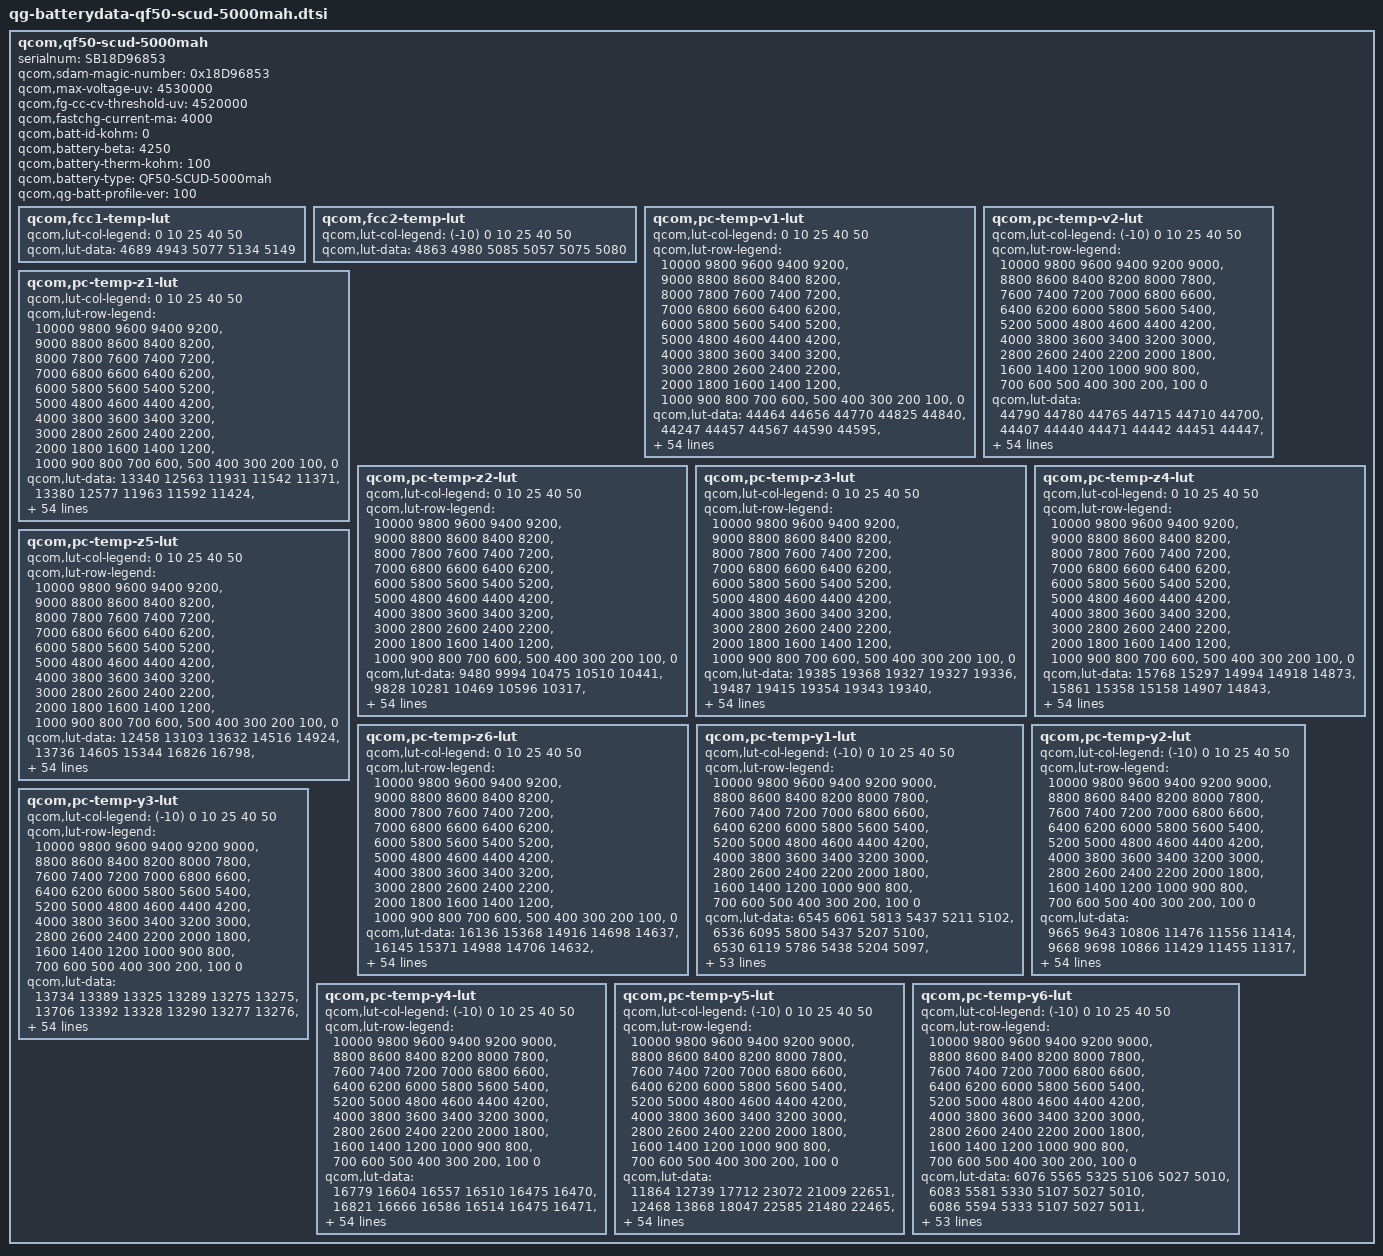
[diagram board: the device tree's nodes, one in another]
/* Copyright (c) 2018, The Linux Foundation. All rights reserved.
 *
 * This program is free software; you can redistribute it and/or modify
 * it under the terms of the GNU General Public License version 2 and
 * only version 2 as published by the Free Software Foundation.
 *
 * This program is distributed in the hope that it will be useful,
 * but WITHOUT ANY WARRANTY; without even the implied warranty of
 * MERCHANTABILITY or FITNESS FOR A PARTICULAR PURPOSE.  See the
 * GNU General Public License for more details.
 */

qcom,qf50-scud-5000mah {
    /* 6691233_Ontim_SQ432_SCUD_5000mAH_PM7250B_averaged_MasterSlave_Sep6th2023 */
    serialnum = "SB18D96853";
    qcom,sdam-magic-number = <0x18D96853>;
    qcom,max-voltage-uv = <4530000>;
    qcom,fg-cc-cv-threshold-uv = <4520000>;
    qcom,fastchg-current-ma = <4000>;
    qcom,batt-id-kohm = <0>;
    qcom,battery-beta = <4250>;
    qcom,battery-therm-kohm = <100>;
    qcom,battery-type = "QF50-SCUD-5000mah";
    qcom,qg-batt-profile-ver = <100>;

	qcom,fcc1-temp-lut {
		qcom,lut-col-legend = <0 10 25 40 50>;
		qcom,lut-data = <4689 4943 5077 5134 5149>;
	};

	qcom,fcc2-temp-lut {
		qcom,lut-col-legend = <(-10) 0 10 25 40 50>;
		qcom,lut-data = <4863 4980 5085 5057 5075 5080>;
	};

	qcom,pc-temp-v1-lut {
		qcom,lut-col-legend = <0 10 25 40 50>;
		qcom,lut-row-legend = <10000 9800 9600 9400 9200>,
			<9000 8800 8600 8400 8200>,
			<8000 7800 7600 7400 7200>,
			<7000 6800 6600 6400 6200>,
			<6000 5800 5600 5400 5200>,
			<5000 4800 4600 4400 4200>,
			<4000 3800 3600 3400 3200>,
			<3000 2800 2600 2400 2200>,
			<2000 1800 1600 1400 1200>,
			<1000 900 800 700 600>,
			<500 400 300 200 100>,
			<0>;
		qcom,lut-data = <44464 44656 44770 44825 44840>,
			<44247 44457 44567 44590 44595>,
			<44029 44254 44372 44395 44395>,
			<43812 44049 44175 44213 44213>,
			<43596 43839 43974 44023 44026>,
			<43373 43621 43767 43820 43827>,
			<43141 43395 43550 43609 43618>,
			<42904 43161 43320 43385 43396>,
			<42664 42915 43080 43150 43161>,
			<42420 42661 42833 42907 42918>,
			<42180 42410 42578 42655 42668>,
			<41944 42162 42325 42401 42414>,
			<41712 41916 42073 42146 42161>,
			<41484 41675 41824 41892 41909>,
			<41262 41440 41580 41644 41661>,
			<41044 41211 41341 41401 41419>,
			<40836 40988 41111 41167 41183>,
			<40633 40773 40889 40943 40953>,
			<40439 40566 40676 40727 40731>,
			<40250 40365 40475 40523 40522>,
			<40067 40167 40278 40331 40332>,
			<39891 39972 40059 40109 40118>,
			<39723 39776 39814 39807 39833>,
			<39560 39568 39574 39519 39548>,
			<39403 39356 39331 39330 39357>,
			<39250 39166 39114 39183 39211>,
			<39109 38994 38979 39052 39072>,
			<38980 38848 38885 38934 38931>,
			<38861 38738 38798 38823 38801>,
			<38754 38647 38707 38710 38689>,
			<38656 38569 38621 38602 38589>,
			<38568 38498 38541 38507 38496>,
			<38497 38434 38466 38423 38411>,
			<38435 38373 38395 38344 38329>,
			<38380 38318 38328 38268 38251>,
			<38330 38265 38263 38195 38175>,
			<38284 38218 38200 38124 38096>,
			<38230 38168 38138 38055 38015>,
			<38169 38099 38061 37973 37923>,
			<38099 38004 37960 37860 37803>,
			<38014 37895 37843 37732 37669>,
			<37909 37762 37712 37608 37538>,
			<37786 37611 37564 37476 37402>,
			<37633 37431 37388 37307 37232>,
			<37455 37276 37232 37157 37089>,
			<37301 37176 37128 37070 37012>,
			<37235 37133 37098 37039 36980>,
			<37180 37103 37070 37019 36958>,
			<37134 37079 37045 36993 36931>,
			<37093 37015 36970 36913 36844>,
			<37038 36773 36688 36617 36532>,
			<36917 36299 36226 36155 36069>,
			<36588 35692 35618 35553 35470>,
			<36036 34841 34782 34727 34646>,
			<35081 33409 33462 33436 33354>,
			<30000 30000 30000 30000 30000>;
	};

	qcom,pc-temp-v2-lut {
		qcom,lut-col-legend = <(-10) 0 10 25 40 50>;
		qcom,lut-row-legend = <10000 9800 9600 9400 9200 9000>,
			<8800 8600 8400 8200 8000 7800>,
			<7600 7400 7200 7000 6800 6600>,
			<6400 6200 6000 5800 5600 5400>,
			<5200 5000 4800 4600 4400 4200>,
			<4000 3800 3600 3400 3200 3000>,
			<2800 2600 2400 2200 2000 1800>,
			<1600 1400 1200 1000 900 800>,
			<700 600 500 400 300 200>,
			<100 0>;
		qcom,lut-data = <44790 44780 44765 44715 44710 44700>,
			<44407 44440 44471 44442 44451 44447>,
			<44068 44142 44206 44190 44210 44211>,
			<43781 43897 43977 43964 43992 43995>,
			<43541 43697 43778 43764 43794 43799>,
			<43314 43500 43576 43559 43591 43597>,
			<43083 43286 43356 43339 43373 43381>,
			<42855 43064 43128 43110 43145 43156>,
			<42621 42834 42890 42873 42909 42921>,
			<42376 42591 42640 42625 42661 42675>,
			<42128 42346 42387 42374 42411 42426>,
			<41884 42103 42134 42123 42159 42175>,
			<41638 41858 41882 41871 41906 41923>,
			<41393 41616 41636 41624 41658 41675>,
			<41151 41379 41395 41380 41414 41429>,
			<40909 41141 41160 41144 41176 41191>,
			<40660 40899 40935 40914 40945 40959>,
			<40404 40655 40708 40693 40722 40735>,
			<40152 40404 40466 40485 40513 40524>,
			<39906 40144 40215 40286 40311 40322>,
			<39665 39890 39959 40064 40094 40108>,
			<39437 39647 39694 39792 39852 39878>,
			<39222 39415 39444 39519 39608 39644>,
			<39018 39201 39226 39292 39369 39402>,
			<38819 39003 39028 39088 39140 39163>,
			<38631 38816 38853 38914 38958 38977>,
			<38481 38631 38698 38767 38815 38832>,
			<38364 38455 38555 38636 38688 38703>,
			<38264 38313 38422 38516 38571 38582>,
			<38176 38195 38297 38407 38463 38470>,
			<38100 38097 38184 38306 38365 38370>,
			<38025 38016 38077 38212 38277 38280>,
			<37949 37947 37984 38124 38191 38194>,
			<37874 37878 37907 38039 38107 38113>,
			<37799 37812 37839 37957 38022 38031>,
			<37724 37744 37776 37872 37926 37929>,
			<37649 37674 37718 37784 37820 37805>,
			<37572 37599 37653 37695 37712 37683>,
			<37494 37518 37580 37609 37609 37573>,
			<37415 37428 37494 37522 37505 37465>,
			<37335 37331 37377 37423 37404 37365>,
			<37254 37228 37224 37313 37301 37264>,
			<37169 37118 37070 37181 37167 37123>,
			<37082 37007 36922 37031 37024 36972>,
			<36997 36889 36802 36902 36916 36869>,
			<36907 36769 36697 36840 36869 36825>,
			<36857 36713 36638 36817 36855 36813>,
			<36807 36661 36571 36786 36837 36793>,
			<36744 36614 36484 36740 36801 36754>,
			<36672 36549 36355 36628 36689 36626>,
			<36596 36448 36094 36307 36349 36261>,
			<36527 36285 35537 35777 35830 35733>,
			<36382 35715 34709 35082 35149 35042>,
			<36077 35032 33716 34072 34187 34063>,
			<35938 34389 32344 32561 32755 32608>,
			<35804 33409 28433 28113 28178 28204>;
	};

	qcom,pc-temp-z1-lut {
		qcom,lut-col-legend = <0 10 25 40 50>;
		qcom,lut-row-legend = <10000 9800 9600 9400 9200>,
			<9000 8800 8600 8400 8200>,
			<8000 7800 7600 7400 7200>,
			<7000 6800 6600 6400 6200>,
			<6000 5800 5600 5400 5200>,
			<5000 4800 4600 4400 4200>,
			<4000 3800 3600 3400 3200>,
			<3000 2800 2600 2400 2200>,
			<2000 1800 1600 1400 1200>,
			<1000 900 800 700 600>,
			<500 400 300 200 100>,
			<0>;
		qcom,lut-data = <13340 12563 11931 11542 11371>,
			<13380 12577 11963 11592 11424>,
			<13400 12588 11990 11592 11417>,
			<13395 12590 12010 11583 11410>,
			<13373 12586 12004 11574 11403>,
			<13358 12576 11983 11567 11395>,
			<13323 12550 11968 11559 11387>,
			<13284 12520 11958 11552 11381>,
			<13258 12499 11950 11544 11375>,
			<13207 12481 11943 11535 11370>,
			<13163 12464 11937 11525 11366>,
			<13149 12444 11929 11516 11363>,
			<13140 12426 11915 11512 11360>,
			<13121 12410 11906 11510 11358>,
			<13058 12395 11908 11508 11356>,
			<12993 12391 11912 11506 11354>,
			<12975 12392 11914 11504 11354>,
			<12966 12392 11914 11502 11354>,
			<12962 12389 11913 11500 11354>,
			<12945 12386 11914 11501 11354>,
			<12920 12388 11915 11503 11353>,
			<12915 12393 11918 11505 11353>,
			<12919 12398 11925 11505 11352>,
			<12925 12403 11930 11505 11352>,
			<12931 12409 11931 11506 11352>,
			<12939 12412 11931 11508 11354>,
			<12946 12416 11933 11511 11356>,
			<12952 12419 11936 11514 11358>,
			<12959 12423 11940 11519 11361>,
			<12968 12432 11949 11522 11364>,
			<12982 12435 11957 11526 11368>,
			<12993 12440 11961 11530 11371>,
			<12991 12447 11966 11536 11375>,
			<12984 12447 11969 11542 11379>,
			<12981 12448 11969 11547 11384>,
			<12996 12451 11971 11551 11390>,
			<13018 12469 11976 11557 11395>,
			<13026 12492 11985 11565 11400>,
			<13027 12500 11995 11572 11405>,
			<13028 12504 12006 11579 11412>,
			<13028 12509 12017 11587 11419>,
			<13028 12521 12027 11595 11424>,
			<13044 12538 12035 11603 11428>,
			<13089 12572 12039 11608 11432>,
			<13180 12580 12046 11614 11437>,
			<13120 12581 12068 11619 11441>,
			<13122 12581 12047 11619 11440>,
			<13120 12586 12056 11623 11442>,
			<13110 12601 12062 11626 11447>,
			<13108 12580 12067 11636 11452>,
			<13120 12619 12081 11637 11458>,
			<13115 12634 12084 11649 11468>,
			<13182 12797 12113 11659 11476>,
			<13134 12675 12129 11677 11492>,
			<13134 12675 12129 11677 11492>,
			<13134 12675 12129 11677 11492>;
	};

	qcom,pc-temp-z2-lut {
		qcom,lut-col-legend = <0 10 25 40 50>;
		qcom,lut-row-legend = <10000 9800 9600 9400 9200>,
			<9000 8800 8600 8400 8200>,
			<8000 7800 7600 7400 7200>,
			<7000 6800 6600 6400 6200>,
			<6000 5800 5600 5400 5200>,
			<5000 4800 4600 4400 4200>,
			<4000 3800 3600 3400 3200>,
			<3000 2800 2600 2400 2200>,
			<2000 1800 1600 1400 1200>,
			<1000 900 800 700 600>,
			<500 400 300 200 100>,
			<0>;
		qcom,lut-data = <9480 9994 10475 10510 10441>,
			<9828 10281 10469 10596 10317>,
			<10056 10456 10660 10724 10497>,
			<10199 10531 10854 10711 10605>,
			<10347 10574 10855 10690 10642>,
			<10383 10572 10803 10673 10613>,
			<10378 10537 10755 10652 10563>,
			<10371 10508 10704 10610 10517>,
			<10363 10496 10649 10544 10466>,
			<10352 10487 10589 10485 10420>,
			<10342 10472 10529 10426 10377>,
			<10328 10435 10512 10391 10340>,
			<10310 10409 10511 10389 10312>,
			<10295 10402 10509 10393 10290>,
			<10281 10397 10507 10398 10272>,
			<10268 10397 10504 10410 10252>,
			<10256 10399 10505 10414 10240>,
			<10245 10402 10519 10363 10248>,
			<10240 10409 10533 10299 10264>,
			<10242 10422 10537 10294 10271>,
			<10247 10434 10541 10309 10275>,
			<10250 10447 10576 10340 10279>,
			<10255 10463 10713 10506 10319>,
			<10262 10493 10794 10667 10372>,
			<10273 10532 10745 10590 10374>,
			<10294 10552 10661 10372 10350>,
			<10310 10561 10605 10302 10374>,
			<10319 10566 10557 10327 10814>,
			<10326 10561 10539 10371 11219>,
			<10334 10547 10558 10514 11096>,
			<10346 10539 10587 10722 10759>,
			<10357 10534 10605 10754 10533>,
			<10360 10530 10620 10659 10369>,
			<10361 10532 10630 10552 10276>,
			<10361 10540 10637 10457 10247>,
			<10357 10544 10643 10382 10232>,
			<10351 10542 10646 10380 10246>,
			<10350 10540 10647 10417 10304>,
			<10352 10543 10651 10461 10362>,
			<10354 10553 10670 10525 10415>,
			<10286 10558 10685 10577 10456>,
			<10064 10547 10680 10572 10467>,
			<9927 10530 10668 10549 10468>,
			<9716 10510 10650 10550 10462>,
			<9960 10529 10631 10552 10463>,
			<9951 10532 10621 10558 10451>,
			<9949 10508 10591 10532 10431>,
			<9987 10443 10543 10546 10442>,
			<9968 10501 10536 10567 10495>,
			<9871 10655 10582 10646 10543>,
			<9864 13526 10583 10573 10446>,
			<9770 10302 10560 10396 10264>,
			<9680 10092 10498 10350 10175>,
			<9490 9962 10407 10281 10113>,
			<9490 9962 10407 10281 10113>,
			<9490 9962 10407 10281 10113>;
	};

	qcom,pc-temp-z3-lut {
		qcom,lut-col-legend = <0 10 25 40 50>;
		qcom,lut-row-legend = <10000 9800 9600 9400 9200>,
			<9000 8800 8600 8400 8200>,
			<8000 7800 7600 7400 7200>,
			<7000 6800 6600 6400 6200>,
			<6000 5800 5600 5400 5200>,
			<5000 4800 4600 4400 4200>,
			<4000 3800 3600 3400 3200>,
			<3000 2800 2600 2400 2200>,
			<2000 1800 1600 1400 1200>,
			<1000 900 800 700 600>,
			<500 400 300 200 100>,
			<0>;
		qcom,lut-data = <19385 19368 19327 19327 19336>,
			<19487 19415 19354 19343 19340>,
			<19553 19449 19381 19360 19364>,
			<19579 19474 19403 19366 19369>,
			<19597 19491 19413 19372 19374>,
			<19601 19496 19419 19382 19381>,
			<19598 19498 19423 19391 19387>,
			<19595 19499 19426 19395 19392>,
			<19593 19501 19429 19398 19397>,
			<19591 19502 19429 19399 19398>,
			<19590 19501 19428 19397 19396>,
			<19588 19498 19427 19395 19393>,
			<19585 19493 19422 19392 19389>,
			<19583 19487 19415 19389 19385>,
			<19582 19482 19411 19386 19381>,
			<19581 19478 19408 19383 19376>,
			<19578 19475 19405 19379 19373>,
			<19572 19472 19402 19374 19369>,
			<19567 19469 19399 19368 19366>,
			<19563 19465 19395 19363 19362>,
			<19560 19464 19392 19359 19357>,
			<19558 19464 19394 19358 19355>,
			<19558 19464 19404 19364 19355>,
			<19559 19468 19411 19371 19357>,
			<19561 19476 19408 19364 19352>,
			<19566 19479 19402 19346 19337>,
			<19569 19480 19397 19340 19334>,
			<19569 19479 19391 19341 19373>,
			<19569 19478 19389 19343 19410>,
			<19568 19475 19389 19356 19408>,
			<19568 19471 19390 19378 19401>,
			<19566 19468 19391 19382 19393>,
			<19564 19465 19393 19380 19385>,
			<19560 19464 19395 19377 19376>,
			<19556 19463 19396 19372 19366>,
			<19553 19463 19397 19365 19356>,
			<19550 19461 19396 19359 19349>,
			<19546 19458 19392 19351 19343>,
			<19540 19455 19389 19348 19339>,
			<19533 19451 19386 19348 19337>,
			<19500 19447 19383 19348 19336>,
			<19414 19443 19380 19347 19338>,
			<19359 19439 19377 19344 19341>,
			<19269 19437 19375 19346 19345>,
			<19263 19427 19369 19346 19345>,
			<19263 19405 19363 19335 19334>,
			<19263 19405 19358 19333 19330>,
			<19263 19378 19357 19327 19323>,
			<19263 19267 19351 19324 19316>,
			<19264 19265 19344 19322 19317>,
			<19264 19264 19350 19337 19334>,
			<19265 19364 19355 19349 19344>,
			<19266 19322 19354 19350 19343>,
			<19281 19341 19355 19352 19342>,
			<19281 19341 19355 19352 19342>,
			<19281 19341 19355 19352 19342>;
	};

	qcom,pc-temp-z4-lut {
		qcom,lut-col-legend = <0 10 25 40 50>;
		qcom,lut-row-legend = <10000 9800 9600 9400 9200>,
			<9000 8800 8600 8400 8200>,
			<8000 7800 7600 7400 7200>,
			<7000 6800 6600 6400 6200>,
			<6000 5800 5600 5400 5200>,
			<5000 4800 4600 4400 4200>,
			<4000 3800 3600 3400 3200>,
			<3000 2800 2600 2400 2200>,
			<2000 1800 1600 1400 1200>,
			<1000 900 800 700 600>,
			<500 400 300 200 100>,
			<0>;
		qcom,lut-data = <15768 15297 14994 14918 14873>,
			<15861 15358 15158 14907 14843>,
			<15882 15372 15125 14949 14898>,
			<15803 15312 15071 14910 14868>,
			<15624 15194 15018 14872 14837>,
			<15473 15102 14958 14841 14813>,
			<15355 15026 14908 14813 14792>,
			<15252 14962 14866 14788 14773>,
			<15169 14910 14831 14767 14756>,
			<15097 14866 14801 14748 14741>,
			<15037 14831 14776 14730 14729>,
			<14985 14801 14755 14718 14720>,
			<14941 14776 14737 14711 14716>,
			<14904 14755 14724 14706 14714>,
			<14873 14737 14716 14701 14711>,
			<14846 14728 14711 14697 14707>,
			<14825 14722 14706 14693 14704>,
			<14808 14718 14702 14690 14701>,
			<14795 14715 14698 14687 14698>,
			<14785 14712 14694 14682 14693>,
			<14778 14712 14692 14676 14686>,
			<14773 14713 14695 14676 14684>,
			<14770 14714 14716 14729 14733>,
			<14768 14722 14745 14792 14796>,
			<14768 14742 14792 14812 14810>,
			<14769 14759 14836 14823 14816>,
			<14770 14775 14839 14825 14814>,
			<14773 14785 14823 14811 14763>,
			<14777 14783 14807 14790 14711>,
			<14780 14776 14792 14763 14702>,
			<14783 14769 14778 14731 14699>,
			<14784 14761 14764 14714 14694>,
			<14784 14753 14751 14703 14690>,
			<14781 14747 14740 14696 14685>,
			<14777 14742 14730 14692 14681>,
			<14772 14737 14722 14688 14678>,
			<14765 14730 14718 14685 14675>,
			<14756 14724 14715 14682 14673>,
			<14743 14718 14714 14681 14673>,
			<14730 14713 14714 14690 14686>,
			<14746 14706 14714 14701 14701>,
			<14816 14697 14708 14697 14698>,
			<14861 14688 14697 14688 14689>,
			<14939 14679 14691 14688 14692>,
			<14890 14659 14674 14681 14688>,
			<14890 14651 14650 14656 14658>,
			<14890 14646 14642 14650 14652>,
			<14889 14669 14633 14638 14641>,
			<14889 14788 14626 14620 14622>,
			<14886 14784 14627 14618 14616>,
			<14884 14785 14642 14641 14653>,
			<14882 14694 14647 14647 14663>,
			<14894 14754 14652 14651 14672>,
			<14916 14759 14658 14656 14679>,
			<14916 14759 14658 14656 14679>,
			<14916 14759 14658 14656 14679>;
	};

	qcom,pc-temp-z5-lut {
		qcom,lut-col-legend = <0 10 25 40 50>;
		qcom,lut-row-legend = <10000 9800 9600 9400 9200>,
			<9000 8800 8600 8400 8200>,
			<8000 7800 7600 7400 7200>,
			<7000 6800 6600 6400 6200>,
			<6000 5800 5600 5400 5200>,
			<5000 4800 4600 4400 4200>,
			<4000 3800 3600 3400 3200>,
			<3000 2800 2600 2400 2200>,
			<2000 1800 1600 1400 1200>,
			<1000 900 800 700 600>,
			<500 400 300 200 100>,
			<0>;
		qcom,lut-data = <12458 13103 13632 14516 14924>,
			<13736 14605 15344 16826 16798>,
			<14841 15819 16835 17866 19005>,
			<15762 16748 18120 18425 20004>,
			<16568 17504 18829 19058 20829>,
			<17239 18144 19319 19978 21728>,
			<17786 18683 19863 21001 22729>,
			<18308 19312 20571 21890 24044>,
			<18910 20275 21392 22743 25688>,
			<19572 21420 22297 23710 27142>,
			<20272 22413 23284 24857 28490>,
			<20994 23257 24237 25935 29436>,
			<21765 24194 25170 26810 29725>,
			<22651 25511 26098 27661 29807>,
			<23777 27043 27003 28741 30024>,
			<24905 28295 27906 30195 30701>,
			<25753 29316 28894 30940 31499>,
			<26447 30265 30034 30762 32836>,
			<27114 31110 31112 30505 34793>,
			<27791 31919 31836 30749 36151>,
			<28456 33054 32586 31622 37436>,
			<29177 34747 35850 32986 37931>,
			<30097 37147 46617 36766 36584>,
			<31336 42352 52815 40112 33818>,
			<33335 49909 48871 35942 28910>,
			<36538 52409 41886 24638 20907>,
			<38981 51917 36791 19924 18533>,
			<40067 51001 32122 18910 27056>,
			<40849 48997 30057 18490 35165>,
			<41422 45332 29688 20775 35458>,
			<42113 42776 29508 25766 35222>,
			<42620 41128 29855 28597 35191>,
			<42417 40127 31369 30368 35222>,
			<41445 40338 33346 31806 34957>,
			<40694 41418 36757 33272 33721>,
			<40485 42427 40019 34394 32246>,
			<40309 43175 41468 34432 32051>,
			<40184 43884 42506 34029 32188>,
			<39996 44644 42728 33848 32244>,
			<39657 45495 42181 34785 31412>,
			<36543 45839 41327 35838 30295>,
			<27594 44517 39640 33957 29862>,
			<21738 43463 37606 29882 29624>,
			<11614 45740 37549 31882 32016>,
			<11503 45268 39072 33655 33964>,
			<11439 31446 40440 29490 28539>,
			<11420 31543 36532 28679 25972>,
			<11392 20941 38420 28277 24753>,
			<11319 11519 33805 34532 29248>,
			<11260 11492 29542 33302 36836>,
			<11234 11682 29224 32033 29811>,
			<11216 17161 26795 30104 25131>,
			<11209 13906 23469 26485 20830>,
			<12090 15413 21805 23002 17424>,
			<12090 15413 21805 23002 17424>,
			<12090 15413 21805 23002 17424>;
	};

	qcom,pc-temp-z6-lut {
		qcom,lut-col-legend = <0 10 25 40 50>;
		qcom,lut-row-legend = <10000 9800 9600 9400 9200>,
			<9000 8800 8600 8400 8200>,
			<8000 7800 7600 7400 7200>,
			<7000 6800 6600 6400 6200>,
			<6000 5800 5600 5400 5200>,
			<5000 4800 4600 4400 4200>,
			<4000 3800 3600 3400 3200>,
			<3000 2800 2600 2400 2200>,
			<2000 1800 1600 1400 1200>,
			<1000 900 800 700 600>,
			<500 400 300 200 100>,
			<0>;
		qcom,lut-data = <16136 15368 14916 14698 14637>,
			<16145 15371 14988 14706 14632>,
			<16131 15366 14973 14728 14666>,
			<16069 15326 14947 14711 14655>,
			<15947 15254 14920 14695 14644>,
			<15836 15195 14886 14684 14637>,
			<15743 15141 14857 14674 14630>,
			<15658 15094 14832 14664 14624>,
			<15586 15054 14809 14654 14618>,
			<15522 15020 14789 14644 14612>,
			<15467 14989 14770 14634 14605>,
			<15417 14961 14754 14625 14598>,
			<15373 14938 14740 14619 14594>,
			<15334 14917 14730 14615 14590>,
			<15300 14900 14723 14610 14586>,
			<15270 14891 14718 14606 14582>,
			<15242 14886 14713 14602 14577>,
			<15216 14883 14709 14597 14574>,
			<15197 14880 14706 14592 14571>,
			<15185 14878 14703 14587 14566>,
			<15177 14877 14701 14583 14560>,
			<15175 14879 14703 14582 14558>,
			<15176 14882 14718 14611 14580>,
			<15178 14889 14735 14640 14608>,
			<15182 14902 14755 14641 14609>,
			<15187 14913 14772 14640 14606>,
			<15193 14923 14772 14637 14604>,
			<15198 14928 14764 14632 14603>,
			<15202 14928 14756 14626 14601>,
			<15206 14925 14752 14623 14598>,
			<15209 14922 14748 14621 14593>,
			<15211 14919 14744 14618 14587>,
			<15212 14916 14741 14613 14582>,
			<15213 14916 14740 14609 14576>,
			<15214 14917 14739 14605 14569>,
			<15215 14918 14738 14601 14563>,
			<15217 14918 14738 14598 14559>,
			<15218 14919 14739 14594 14555>,
			<15221 14920 14740 14592 14554>,
			<15224 14923 14743 14598 14559>,
			<15227 14926 14746 14604 14565>,
			<15231 14928 14745 14603 14566>,
			<15237 14931 14744 14600 14565>,
			<15249 14937 14746 14602 14568>,
			<15258 14937 14743 14600 14567>,
			<15264 14931 14735 14585 14549>,
			<15266 14931 14730 14581 14545>,
			<15267 14927 14727 14574 14537>,
			<15268 14927 14723 14566 14525>,
			<15270 14932 14726 14566 14525>,
			<15276 14943 14740 14585 14550>,
			<15290 14962 14751 14596 14562>,
			<15308 14976 14760 14602 14569>,
			<15338 15004 14773 14610 14575>,
			<15338 15004 14773 14610 14575>,
			<15338 15004 14773 14610 14575>;
	};

	qcom,pc-temp-y1-lut {
		qcom,lut-col-legend = <(-10) 0 10 25 40 50>;
		qcom,lut-row-legend = <10000 9800 9600 9400 9200 9000>,
			<8800 8600 8400 8200 8000 7800>,
			<7600 7400 7200 7000 6800 6600>,
			<6400 6200 6000 5800 5600 5400>,
			<5200 5000 4800 4600 4400 4200>,
			<4000 3800 3600 3400 3200 3000>,
			<2800 2600 2400 2200 2000 1800>,
			<1600 1400 1200 1000 900 800>,
			<700 600 500 400 300 200>,
			<100 0>;
		qcom,lut-data = <6545 6061 5813 5437 5211 5102>,
			<6536 6095 5800 5437 5207 5100>,
			<6530 6119 5786 5438 5204 5097>,
			<6526 6135 5774 5439 5200 5094>,
			<6525 6144 5766 5439 5196 5091>,
			<6524 6147 5763 5440 5193 5088>,
			<6536 6138 5765 5440 5188 5084>,
			<6562 6124 5768 5440 5184 5080>,
			<6570 6123 5771 5439 5182 5078>,
			<6556 6128 5774 5435 5180 5076>,
			<6539 6131 5775 5431 5178 5073>,
			<6534 6138 5768 5428 5174 5070>,
			<6534 6151 5760 5425 5170 5068>,
			<6535 6154 5760 5423 5167 5065>,
			<6538 6154 5763 5419 5163 5063>,
			<6543 6154 5764 5418 5160 5063>,
			<6543 6154 5765 5420 5158 5063>,
			<6542 6153 5766 5423 5157 5062>,
			<6540 6154 5769 5422 5157 5062>,
			<6537 6157 5775 5420 5157 5061>,
			<6532 6159 5777 5420 5158 5060>,
			<6534 6157 5771 5422 5158 5060>,
			<6555 6152 5767 5426 5158 5060>,
			<6572 6152 5768 5429 5160 5061>,
			<6573 6165 5772 5432 5162 5062>,
			<6572 6175 5776 5435 5164 5064>,
			<6571 6168 5783 5437 5165 5065>,
			<6557 6154 5787 5440 5166 5066>,
			<6543 6149 5787 5443 5168 5067>,
			<6543 6153 5785 5448 5170 5068>,
			<6548 6156 5785 5450 5173 5070>,
			<6550 6150 5787 5451 5176 5073>,
			<6540 6139 5789 5451 5179 5075>,
			<6527 6135 5785 5452 5182 5078>,
			<6525 6142 5780 5454 5185 5080>,
			<6524 6147 5780 5456 5188 5082>,
			<6523 6143 5788 5458 5190 5084>,
			<6533 6133 5793 5460 5192 5086>,
			<6551 6131 5795 5463 5193 5087>,
			<6553 6139 5796 5465 5195 5088>,
			<6532 6146 5792 5466 5196 5090>,
			<6515 6144 5780 5463 5198 5093>,
			<6518 6141 5776 5463 5199 5095>,
			<6524 6134 5778 5469 5203 5097>,
			<6527 6133 5783 5484 5209 5101>,
			<6542 6156 5970 5475 5211 5103>,
			<6575 6149 5817 5488 5213 5104>,
			<6587 6139 5794 5485 5212 5104>,
			<6664 6164 5777 5480 5214 5106>,
			<6772 6174 5779 5478 5215 5105>,
			<6796 6255 5822 5482 5217 5109>,
			<6867 6342 5884 5490 5223 5114>,
			<6956 6678 6057 5506 5229 5119>,
			<7317 6768 6471 5526 5240 5131>,
			<7317 6768 6471 5526 5240 5131>,
			<7317 6768 6471 5526 5240 5131>;
	};

	qcom,pc-temp-y2-lut {
		qcom,lut-col-legend = <(-10) 0 10 25 40 50>;
		qcom,lut-row-legend = <10000 9800 9600 9400 9200 9000>,
			<8800 8600 8400 8200 8000 7800>,
			<7600 7400 7200 7000 6800 6600>,
			<6400 6200 6000 5800 5600 5400>,
			<5200 5000 4800 4600 4400 4200>,
			<4000 3800 3600 3400 3200 3000>,
			<2800 2600 2400 2200 2000 1800>,
			<1600 1400 1200 1000 900 800>,
			<700 600 500 400 300 200>,
			<100 0>;
		qcom,lut-data = <9665 9643 10806 11476 11556 11414>,
			<9668 9698 10866 11429 11455 11317>,
			<9671 10016 10954 11382 11344 11211>,
			<9674 10361 11046 11337 11235 11108>,
			<9677 10650 11116 11298 11140 11023>,
			<9681 10801 11142 11269 11072 10969>,
			<9685 10842 11133 11249 11020 10942>,
			<9688 10868 11121 11231 10979 10921>,
			<9691 10887 11117 11203 10960 10891>,
			<9692 10903 11122 11165 10945 10853>,
			<9693 10916 11125 11148 10934 10836>,
			<9694 10928 11129 11158 10929 10834>,
			<9696 10940 11138 11178 10928 10832>,
			<9696 10963 11154 11201 10927 10826>,
			<9693 11015 11189 11233 10930 10815>,
			<9689 11057 11230 11269 10942 10807>,
			<9688 11075 11287 11315 10966 10803>,
			<9687 11087 11333 11365 11003 10801>,
			<9687 11088 11344 11419 11092 10829>,
			<9684 11078 11342 11479 11247 10916>,
			<9681 11061 11327 11497 11334 11024>,
			<9678 11037 11271 11444 11337 11202>,
			<9677 11002 11226 11377 11316 11323>,
			<9676 10968 11220 11349 11283 11267>,
			<9675 10936 11218 11330 11232 11150>,
			<9674 10883 11215 11322 11228 11122>,
			<9673 10556 11210 11356 11243 11145>,
			<9672 10008 11203 11394 11264 11166>,
			<9671 9808 11179 11411 11324 11183>,
			<9670 9757 11144 11440 11408 11203>,
			<9668 9730 11136 11463 11428 11221>,
			<9667 9718 11149 11491 11429 11304>,
			<9667 9711 11156 11507 11429 11367>,
			<9666 9703 11137 11482 11435 11387>,
			<9666 9696 11099 11424 11449 11404>,
			<9665 9689 11048 11386 11451 11398>,
			<9664 9683 10969 11355 11427 11372>,
			<9664 9678 10870 11342 11404 11347>,
			<9664 9674 10760 11364 11382 11303>,
			<9663 9671 10611 11398 11355 11253>,
			<9663 9668 10289 11399 11356 11235>,
			<9662 9666 9826 11364 11382 11227>,
			<9661 9664 9719 11264 11347 11190>,
			<9660 9662 9689 11042 11248 11114>,
			<9659 9661 9679 10878 11204 11052>,
			<9657 9659 9671 10980 11104 10941>,
			<9655 9658 9666 10986 11162 10922>,
			<9653 9656 9661 10985 11237 10965>,
			<9651 9653 9658 11055 11251 10963>,
			<9650 9651 9655 11104 11228 10928>,
			<9649 9649 9652 10908 11072 10844>,
			<9648 9648 9650 10589 11002 10785>,
			<9648 9648 9649 10463 10917 10692>,
			<9648 9649 9648 10017 10750 10519>,
			<9648 9649 9648 10017 10750 10519>,
			<9648 9649 9648 10017 10750 10519>;
	};

	qcom,pc-temp-y3-lut {
		qcom,lut-col-legend = <(-10) 0 10 25 40 50>;
		qcom,lut-row-legend = <10000 9800 9600 9400 9200 9000>,
			<8800 8600 8400 8200 8000 7800>,
			<7600 7400 7200 7000 6800 6600>,
			<6400 6200 6000 5800 5600 5400>,
			<5200 5000 4800 4600 4400 4200>,
			<4000 3800 3600 3400 3200 3000>,
			<2800 2600 2400 2200 2000 1800>,
			<1600 1400 1200 1000 900 800>,
			<700 600 500 400 300 200>,
			<100 0>;
		qcom,lut-data = <13734 13389 13325 13289 13275 13275>,
			<13706 13392 13328 13290 13277 13276>,
			<13679 13395 13331 13291 13278 13277>,
			<13653 13398 13335 13292 13280 13278>,
			<13630 13400 13337 13293 13281 13279>,
			<13613 13401 13339 13295 13282 13280>,
			<13601 13400 13340 13296 13283 13281>,
			<13592 13400 13340 13297 13284 13282>,
			<13582 13399 13340 13298 13285 13283>,
			<13571 13397 13340 13299 13285 13284>,
			<13561 13394 13340 13300 13286 13285>,
			<13551 13392 13339 13300 13287 13286>,
			<13542 13389 13337 13301 13288 13287>,
			<13535 13387 13336 13301 13288 13287>,
			<13531 13384 13334 13300 13289 13287>,
			<13528 13381 13333 13300 13289 13287>,
			<13523 13377 13332 13298 13290 13288>,
			<13517 13373 13331 13297 13291 13289>,
			<13512 13368 13329 13297 13291 13290>,
			<13508 13362 13326 13297 13292 13292>,
			<13505 13356 13322 13297 13292 13292>,
			<13504 13351 13318 13295 13289 13290>,
			<13502 13347 13314 13292 13285 13286>,
			<13501 13343 13311 13290 13282 13282>,
			<13499 13339 13309 13288 13279 13278>,
			<13495 13336 13308 13287 13278 13277>,
			<13495 13333 13306 13287 13278 13278>,
			<13505 13331 13305 13286 13278 13278>,
			<13523 13330 13304 13287 13278 13277>,
			<13544 13330 13303 13287 13278 13275>,
			<13572 13331 13303 13287 13278 13275>,
			<13602 13334 13303 13287 13278 13275>,
			<13632 13342 13303 13286 13278 13275>,
			<13665 13351 13303 13286 13278 13277>,
			<13705 13363 13303 13285 13278 13278>,
			<13754 13378 13305 13285 13278 13278>,
			<13807 13399 13307 13285 13278 13277>,
			<13863 13426 13310 13285 13277 13277>,
			<13924 13461 13314 13285 13277 13277>,
			<13991 13507 13319 13285 13278 13277>,
			<14066 13565 13329 13286 13278 13278>,
			<14147 13635 13344 13286 13278 13279>,
			<14232 13723 13359 13287 13277 13278>,
			<14333 13837 13382 13287 13276 13276>,
			<14471 13984 13425 13288 13277 13276>,
			<14729 14175 13508 13292 13282 13282>,
			<15015 14337 13609 13294 13284 13285>,
			<15462 14606 13787 13297 13287 13286>,
			<16369 15240 14100 13302 13288 13287>,
			<18307 17007 14676 13305 13287 13285>,
			<22468 22128 16241 13304 13283 13282>,
			<32390 39066 22243 13307 13285 13282>,
			<60521 65535 48032 13321 13288 13286>,
			<65535 65535 65535 13348 13294 13294>,
			<65535 65535 65535 13348 13294 13294>,
			<65535 65535 65535 13348 13294 13294>;
	};

	qcom,pc-temp-y4-lut {
		qcom,lut-col-legend = <(-10) 0 10 25 40 50>;
		qcom,lut-row-legend = <10000 9800 9600 9400 9200 9000>,
			<8800 8600 8400 8200 8000 7800>,
			<7600 7400 7200 7000 6800 6600>,
			<6400 6200 6000 5800 5600 5400>,
			<5200 5000 4800 4600 4400 4200>,
			<4000 3800 3600 3400 3200 3000>,
			<2800 2600 2400 2200 2000 1800>,
			<1600 1400 1200 1000 900 800>,
			<700 600 500 400 300 200>,
			<100 0>;
		qcom,lut-data = <16779 16604 16557 16510 16475 16470>,
			<16821 16666 16586 16514 16475 16471>,
			<16912 16742 16635 16520 16475 16472>,
			<17020 16819 16688 16527 16475 16473>,
			<17113 16884 16731 16532 16475 16473>,
			<17159 16922 16750 16534 16475 16474>,
			<17159 16940 16755 16533 16475 16473>,
			<17158 16951 16757 16532 16475 16473>,
			<17155 16951 16754 16532 16475 16473>,
			<17144 16944 16743 16531 16476 16473>,
			<17128 16938 16737 16531 16477 16473>,
			<17116 16934 16735 16532 16478 16474>,
			<17104 16931 16734 16535 16481 16475>,
			<17090 16930 16737 16541 16484 16476>,
			<17074 16928 16748 16551 16489 16479>,
			<17054 16926 16760 16564 16495 16483>,
			<17027 16918 16774 16582 16502 16487>,
			<16988 16902 16784 16603 16511 16492>,
			<16946 16880 16777 16628 16528 16502>,
			<16903 16842 16753 16656 16553 16516>,
			<16860 16799 16723 16664 16561 16527>,
			<16817 16761 16674 16619 16557 16536>,
			<16775 16722 16627 16560 16549 16542>,
			<16737 16688 16596 16524 16521 16521>,
			<16699 16656 16571 16496 16476 16478>,
			<16666 16629 16557 16487 16464 16465>,
			<16652 16603 16548 16485 16465 16463>,
			<16647 16581 16540 16485 16466 16463>,
			<16645 16571 16533 16488 16471 16466>,
			<16643 16565 16526 16494 16479 16474>,
			<16642 16563 16516 16501 16489 16482>,
			<16642 16565 16503 16510 16501 16493>,
			<16646 16570 16497 16516 16510 16503>,
			<16652 16576 16500 16519 16515 16513>,
			<16657 16584 16506 16521 16518 16522>,
			<16662 16592 16516 16519 16516 16519>,
			<16668 16600 16533 16506 16502 16502>,
			<16676 16607 16549 16495 16489 16490>,
			<16687 16613 16566 16493 16481 16487>,
			<16698 16618 16578 16492 16476 16485>,
			<16712 16623 16576 16494 16477 16489>,
			<16727 16626 16568 16501 16483 16499>,
			<16744 16630 16568 16502 16476 16486>,
			<16760 16638 16574 16495 16456 16457>,
			<16768 16649 16577 16491 16447 16446>,
			<16783 16645 16599 16502 16469 16481>,
			<16810 16644 16625 16523 16498 16518>,
			<16843 16655 16657 16551 16534 16556>,
			<16912 16706 16705 16595 16570 16588>,
			<17143 16915 16758 16622 16569 16574>,
			<17635 17602 17026 16587 16498 16495>,
			<19172 21459 18977 16571 16483 16486>,
			<19831 19330 37121 16598 16486 16485>,
			<17100 16972 65535 16656 16495 16485>,
			<17100 16972 65535 16656 16495 16485>,
			<17100 16972 65535 16656 16495 16485>;
	};

	qcom,pc-temp-y5-lut {
		qcom,lut-col-legend = <(-10) 0 10 25 40 50>;
		qcom,lut-row-legend = <10000 9800 9600 9400 9200 9000>,
			<8800 8600 8400 8200 8000 7800>,
			<7600 7400 7200 7000 6800 6600>,
			<6400 6200 6000 5800 5600 5400>,
			<5200 5000 4800 4600 4400 4200>,
			<4000 3800 3600 3400 3200 3000>,
			<2800 2600 2400 2200 2000 1800>,
			<1600 1400 1200 1000 900 800>,
			<700 600 500 400 300 200>,
			<100 0>;
		qcom,lut-data = <11864 12739 17712 23072 21009 22651>,
			<12468 13868 18047 22585 21480 22465>,
			<13100 15062 18397 22102 21760 22337>,
			<13759 16217 18733 21651 21896 22257>,
			<14444 17227 19025 21264 21933 22216>,
			<15153 17987 19244 20974 21917 22204>,
			<15988 18593 19437 20789 21626 22285>,
			<16844 19070 19574 20628 21081 22356>,
			<17271 19228 19564 20326 20463 22167>,
			<17439 19298 19443 19730 19645 21639>,
			<17565 19330 19271 19172 18986 21184>,
			<17708 19328 18888 18718 18568 20856>,
			<17849 19336 18502 18221 18176 20493>,
			<18036 19433 18379 17554 17647 19903>,
			<18400 19769 18309 16667 17009 18923>,
			<18781 20196 18324 16104 16562 18131>,
			<18979 20697 18943 15795 16170 17532>,
			<19154 21285 19899 15612 15919 17055>,
			<19238 21757 20909 16005 15839 16711>,
			<19169 22132 22057 17516 15661 16428>,
			<19055 22489 22880 19343 15923 16528>,
			<19005 22905 23516 22089 18830 18435>,
			<18864 23309 23966 24373 21482 20413>,
			<18628 23545 24190 24830 21810 21153>,
			<17475 23752 24347 24828 21906 21636>,
			<15302 23863 24507 24684 21756 21674>,
			<14170 21883 24687 23946 20857 21074>,
			<13683 17817 24794 23346 19886 20167>,
			<13429 15671 24809 23538 19280 18607>,
			<13539 14513 24814 24022 18814 16793>,
			<13883 13963 24940 24391 18753 16348>,
			<14035 14063 25453 24683 18958 16385>,
			<13926 14319 25747 24951 19254 16572>,
			<13794 14542 25116 25331 19796 17723>,
			<13809 14783 24292 25833 20631 19554>,
			<13947 14986 24109 26049 21697 20918>,
			<14050 15191 24058 26155 23182 22169>,
			<14082 15439 24087 26207 24057 22687>,
			<14102 15485 24282 26005 24224 22582>,
			<14117 15347 24469 25476 24174 22431>,
			<14145 15160 23315 24812 23740 22536>,
			<14159 14915 19644 23754 22681 22986>,
			<14051 14637 16704 23000 22521 23123>,
			<13893 14611 15215 22496 22652 22762>,
			<14096 14328 15136 20765 21288 20206>,
			<14198 13971 14810 21177 19870 17863>,
			<13780 13961 14497 20342 18793 16794>,
			<12952 13894 14617 19515 18084 15840>,
			<12071 13351 14728 19640 17444 15497>,
			<11219 11688 14833 20193 17078 15210>,
			<10460 10365 12788 19765 17785 15983>,
			<9999 9628 9945 19131 18659 15311>,
			<14564 15570 9045 18813 18334 15195>,
			<31473 20402 8850 15837 19903 18744>,
			<31473 20402 8850 15837 19903 18744>,
			<31473 20402 8850 15837 19903 18744>;
	};

	qcom,pc-temp-y6-lut {
		qcom,lut-col-legend = <(-10) 0 10 25 40 50>;
		qcom,lut-row-legend = <10000 9800 9600 9400 9200 9000>,
			<8800 8600 8400 8200 8000 7800>,
			<7600 7400 7200 7000 6800 6600>,
			<6400 6200 6000 5800 5600 5400>,
			<5200 5000 4800 4600 4400 4200>,
			<4000 3800 3600 3400 3200 3000>,
			<2800 2600 2400 2200 2000 1800>,
			<1600 1400 1200 1000 900 800>,
			<700 600 500 400 300 200>,
			<100 0>;
		qcom,lut-data = <6076 5565 5325 5106 5027 5010>,
			<6083 5581 5330 5107 5027 5010>,
			<6086 5594 5333 5107 5027 5011>,
			<6085 5604 5335 5107 5028 5011>,
			<6082 5610 5335 5106 5028 5012>,
			<6077 5612 5335 5106 5028 5012>,
			<6071 5610 5332 5105 5028 5013>,
			<6061 5604 5325 5104 5028 5013>,
			<6051 5598 5319 5102 5028 5014>,
			<6037 5590 5311 5101 5028 5014>,
			<6024 5582 5305 5100 5028 5014>,
			<6012 5574 5299 5100 5029 5015>,
			<6001 5568 5294 5100 5030 5016>,
			<5990 5562 5293 5101 5031 5017>,
			<5981 5559 5291 5102 5032 5017>,
			<5972 5554 5291 5105 5034 5019>,
			<5961 5548 5292 5108 5036 5020>,
			<5949 5540 5293 5113 5039 5022>,
			<5936 5530 5290 5120 5044 5026>,
			<5924 5517 5279 5128 5052 5031>,
			<5913 5503 5267 5130 5054 5034>,
			<5904 5491 5251 5116 5050 5034>,
			<5895 5480 5236 5097 5045 5033>,
			<5889 5471 5226 5086 5035 5025>,
			<5884 5465 5219 5077 5020 5009>,
			<5879 5459 5216 5074 5016 5005>,
			<5879 5452 5214 5075 5016 5005>,
			<5891 5446 5214 5075 5017 5005>,
			<5909 5445 5214 5077 5018 5005>,
			<5928 5450 5214 5080 5021 5007>,
			<5951 5459 5215 5083 5024 5009>,
			<5977 5472 5216 5086 5028 5012>,
			<6004 5491 5218 5089 5031 5015>,
			<6035 5513 5223 5092 5033 5019>,
			<6069 5538 5232 5093 5034 5023>,
			<6108 5567 5244 5094 5033 5022>,
			<6151 5601 5261 5091 5030 5017>,
			<6198 5641 5282 5089 5026 5014>,
			<6249 5685 5306 5091 5025 5013>,
			<6304 5736 5334 5093 5024 5013>,
			<6365 5793 5361 5097 5024 5014>,
			<6432 5857 5390 5103 5027 5019>,
			<6506 5933 5430 5107 5024 5014>,
			<6596 6028 5487 5111 5019 5005>,
			<6714 6154 5552 5117 5018 5003>,
			<6939 6318 5666 5128 5028 5017>,
			<7193 6447 5769 5139 5039 5030>,
			<7582 6667 5936 5153 5051 5042>,
			<8337 7193 6206 5172 5062 5052>,
			<9861 8575 6669 5186 5061 5047>,
			<12956 12364 7929 5181 5038 5023>,
			<20121 24746 12701 5192 5036 5021>,
			<39446 65535 35327 5242 5041 5025>,
			<65535 65535 65535 5325 5050 5032>,
			<65535 65535 65535 5325 5050 5032>,
			<65535 65535 65535 5325 5050 5032>;
	};

};
